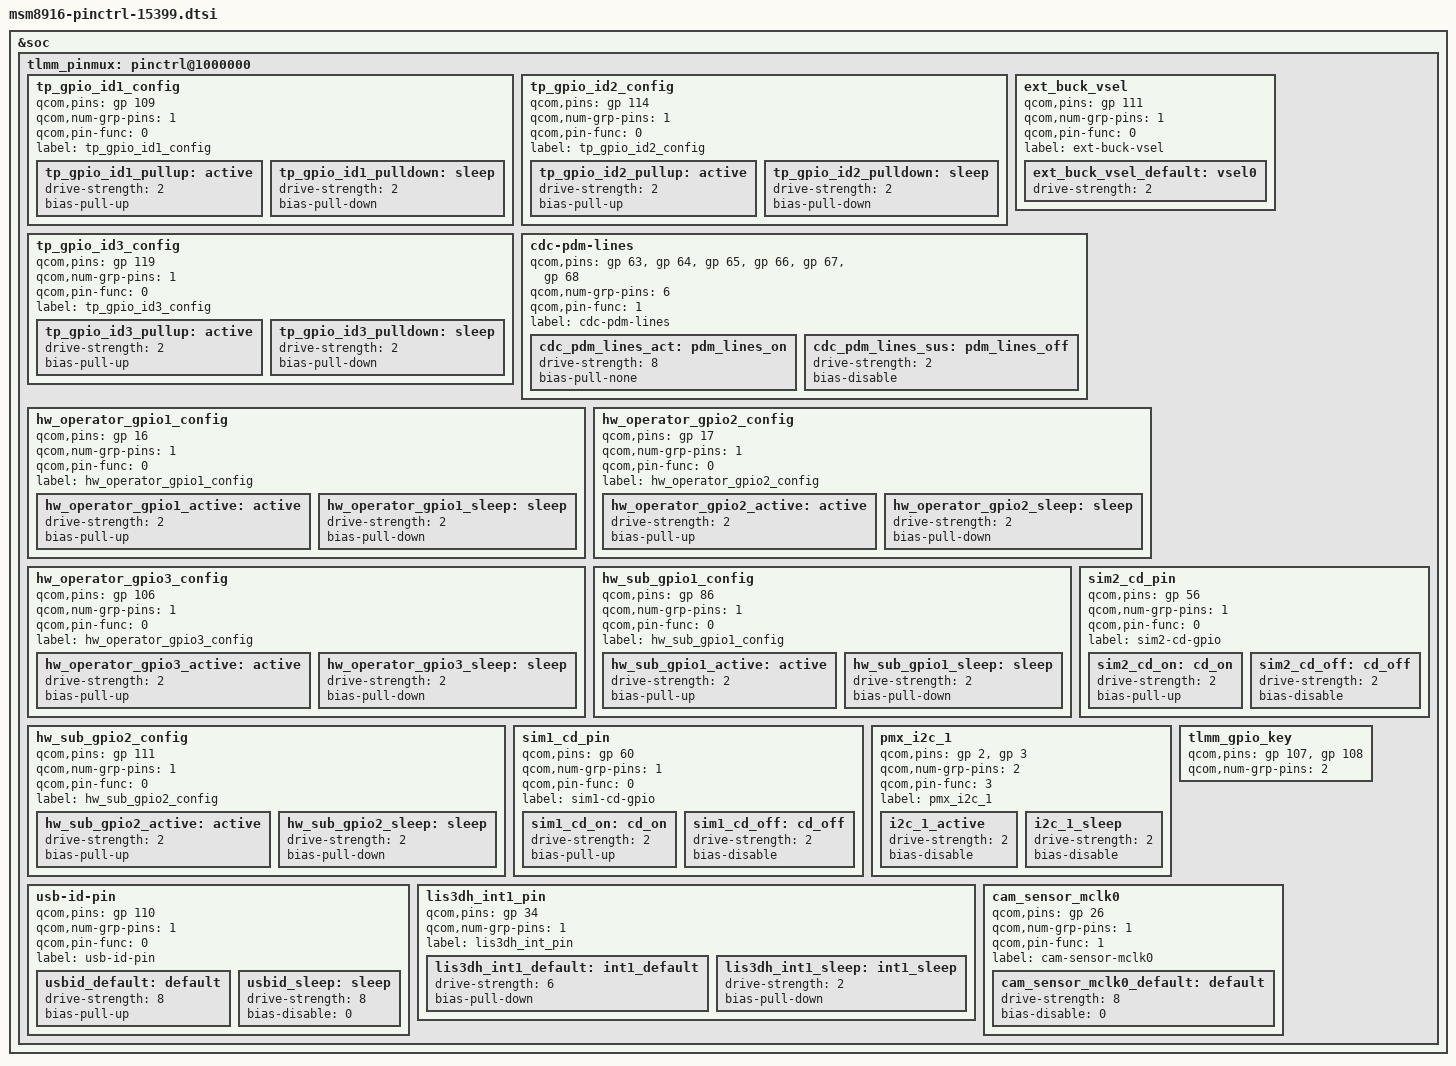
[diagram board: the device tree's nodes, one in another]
/* Copyright (c) 2013-2014, The Linux Foundation. All rights reserved.
 *
 * This program is free software; you can redistribute it and/or modify
 * it under the terms of the GNU General Public License version 2 and
 * only version 2 as published by the Free Software Foundation.
 *
 * This program is distributed in the hope that it will be useful,
 * but WITHOUT ANY WARRANTY; without even the implied warranty of
 * MERCHANTABILITY or FITNESS FOR A PARTICULAR PURPOSE.  See the
 * GNU General Public License for more details.
 */

&soc {
	tlmm_pinmux: pinctrl@1000000 {
		tp_gpio_id1_config {
			/* MCLK */
			qcom,pins = <&gp 109>;
			qcom,num-grp-pins = <1>;
			qcom,pin-func = <0>;
			label = "tp_gpio_id1_config";
			/* active state */
			tp_gpio_id1_pullup: active {
				drive-strength = <2>; /* 2 mA */
				bias-pull-up; /*  PULL  UP*/
			};
			tp_gpio_id1_pulldown: sleep {
				drive-strength = <2>; /* 2 mA */
				bias-pull-down; /* PULL DOWN */
			};			
		};

		tp_gpio_id2_config {
			/* MCLK */
			qcom,pins = <&gp 114>;
			qcom,num-grp-pins = <1>;
			qcom,pin-func = <0>;
			label = "tp_gpio_id2_config";
			/* active state */
			tp_gpio_id2_pullup: active {
				drive-strength = <2>; /* 2 mA */
				bias-pull-up; /*  PULL  UP*/
			};
			tp_gpio_id2_pulldown: sleep {
				drive-strength = <2>; /* 2 mA */
				bias-pull-down; /* PULL DOWN */
			};			
		};

		tp_gpio_id3_config {
			/* MCLK */
			qcom,pins = <&gp 119>;
			qcom,num-grp-pins = <1>;
			qcom,pin-func = <0>;
			label = "tp_gpio_id3_config";
			/* active state */
			tp_gpio_id3_pullup: active {
				drive-strength = <2>; /* 2 mA */
				bias-pull-up; /*  PULL  UP*/
			};
			tp_gpio_id3_pulldown: sleep {
				drive-strength = <2>; /* 2 mA */
				bias-pull-down; /* PULL DOWN */
			};			
		};

                ext_buck_vsel {
			qcom,pins = <&gp 111>;
			qcom,num-grp-pins = <1>;
			qcom,pin-func = <0>;
			label = "ext-buck-vsel";

			ext_buck_vsel_default: vsel0 {
				drive-strength = <2>;
			};
		};

                cdc-pdm-lines {
			qcom,pins = <&gp 63>, <&gp 64>, <&gp 65>,
					<&gp 66>, <&gp 67>, <&gp 68>;
			qcom,num-grp-pins = <6>;
			qcom,pin-func = <1>;
			label = "cdc-pdm-lines";
			cdc_pdm_lines_act: pdm_lines_on {
				drive-strength = <8>;
				bias-pull-none;
			};
			cdc_pdm_lines_sus: pdm_lines_off {
				drive-strength = <2>;
				bias-disable;
			};
		};

                hw_operator_gpio1_config {
			/* MCLK */
			qcom,pins = <&gp 16>;
			qcom,num-grp-pins = <1>;
			qcom,pin-func = <0>;
			label = "hw_operator_gpio1_config";
			/* active state */
			hw_operator_gpio1_active: active {
				drive-strength = <2>; /* 2 mA */
				bias-pull-up; /*  PULL  UP*/
			};
			hw_operator_gpio1_sleep: sleep {
				drive-strength = <2>; /* 2 mA */
				bias-pull-down; /* PULL DOWN */
			};			
		};

		hw_operator_gpio2_config {
			/* MCLK */
			qcom,pins = <&gp 17>;
			qcom,num-grp-pins = <1>;
			qcom,pin-func = <0>;
			label = "hw_operator_gpio2_config";
			/* active state */
			hw_operator_gpio2_active: active {
				drive-strength = <2>; /* 2 mA */
				bias-pull-up; /*  PULL  UP*/
			};
			hw_operator_gpio2_sleep: sleep {
				drive-strength = <2>; /* 2 mA */
				bias-pull-down; /* PULL DOWN */
			};			
		};

		hw_operator_gpio3_config {
			/* MCLK */
			qcom,pins = <&gp 106>;
			qcom,num-grp-pins = <1>;
			qcom,pin-func = <0>;
			label = "hw_operator_gpio3_config";
			/* active state */
			hw_operator_gpio3_active: active {
				drive-strength = <2>; /* 2 mA */
				bias-pull-up; /*  PULL  UP*/
			};
			hw_operator_gpio3_sleep: sleep {
				drive-strength = <2>; /* 2 mA */
				bias-pull-down; /* PULL DOWN */
			};			
		};

                hw_sub_gpio1_config {
			/* MCLK */
			qcom,pins = <&gp 86>;
			qcom,num-grp-pins = <1>;
			qcom,pin-func = <0>;
			label = "hw_sub_gpio1_config";
			/* active state */
			hw_sub_gpio1_active: active {
				drive-strength = <2>; /* 2 mA */
				bias-pull-up; /*  PULL  UP*/
			};
			hw_sub_gpio1_sleep: sleep {
				drive-strength = <2>; /* 2 mA */
				bias-pull-down; /* PULL DOWN */
			};			
		};

		hw_sub_gpio2_config {
			/* MCLK */
			qcom,pins = <&gp 111>;
			qcom,num-grp-pins = <1>;
			qcom,pin-func = <0>;
			label = "hw_sub_gpio2_config";
			/* active state */
			hw_sub_gpio2_active: active {
				drive-strength = <2>; /* 2 mA */
				bias-pull-up; /*  PULL  UP*/
			};
			hw_sub_gpio2_sleep: sleep {
				drive-strength = <2>; /* 2 mA */
				bias-pull-down; /* PULL DOWN */
			};			
		};

                sim2_cd_pin {
			qcom,pins = <&gp 56>;
			qcom,num-grp-pins = <1>;
			qcom,pin-func = <0>;
			label = "sim2-cd-gpio";

			sim2_cd_on: cd_on {
				drive-strength = <2>;
				bias-pull-up;
			};

			sim2_cd_off: cd_off {
				drive-strength = <2>;
				bias-disable;
			};
		};

		sim1_cd_pin {
			qcom,pins = <&gp 60>;
			qcom,num-grp-pins = <1>;
			qcom,pin-func = <0>;
			label = "sim1-cd-gpio";

			sim1_cd_on: cd_on {
				drive-strength = <2>;
				bias-pull-up;
			};

			sim1_cd_off: cd_off {
				drive-strength = <2>;
				bias-disable;
			};
		};

                pmx_i2c_1 {
			qcom,pins = <&gp 2>, <&gp 3>;
			qcom,num-grp-pins = <2>;
			qcom,pin-func = <3>;
			label = "pmx_i2c_1";

			i2c_1_active: i2c_1_active {
				drive-strength = <2>;
				bias-disable;
			};

			i2c_1_sleep: i2c_1_sleep {
				drive-strength = <2>;
				bias-disable;
			};
		};

                tlmm_gpio_key {
                        qcom,pins = <&gp 107> , <&gp 108>;
                        qcom,num-grp-pins = <2>;
                };

                usb-id-pin {
			qcom,pins = <&gp 110>;
			qcom,num-grp-pins = <1>;
			qcom,pin-func = <0>;
			label = "usb-id-pin";
			usbid_default: default {
				drive-strength = <8>;
				bias-pull-up;
			};
			usbid_sleep: sleep {
				drive-strength = <8>;
				bias-disable = <0>;
			};
		};

                lis3dh_int1_pin {
			qcom,pins = <&gp 34>;
			qcom,num-grp-pins = <1>;
			label = "lis3dh_int_pin";

			lis3dh_int1_default: int1_default {
				drive-strength = <6>;
				bias-pull-down;
			};

			lis3dh_int1_sleep: int1_sleep {
				drive-strength = <2>;
				bias-pull-down;
			};
		};

                cam_sensor_mclk0 {
			/* MCLK */
			qcom,pins = <&gp 26>;
			qcom,num-grp-pins = <1>;
			qcom,pin-func = <1>;
			label = "cam-sensor-mclk0";
			/* active state */
			cam_sensor_mclk0_default: default {
				drive-strength = <8>; /* 2 MA */
				bias-disable = <0>; /* No PULL */
			};
		};
	};
};
